# LPC55S14 register map
Vendor: nxp.com; File version: 1.0
CPU: CM33 r2p0, little endian, MPU, FPU, VTOR, 3 interrupt priority bits
Registers are 32-bit, read-write, reset 0x0 unless marked. A register's access mark holds for its fields unless they carry their own. Offsets are from the block's base; [hi:lo] are bit positions; {n}, {i} and the like mark numbered series; 'fields as' and 'values as' point back to an identical list.

## PMC
Base 0x40020000
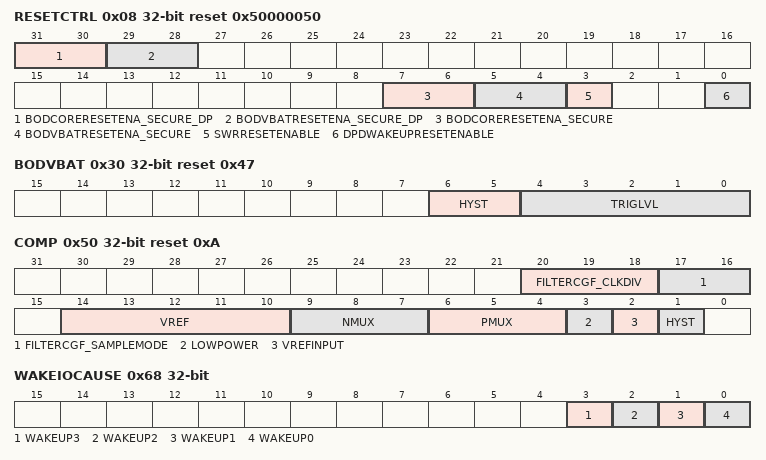
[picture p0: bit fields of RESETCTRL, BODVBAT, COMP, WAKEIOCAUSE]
0x08 RESETCTRL reset 0x50000050 — Reset Control [Reset by: PoR, Pin Reset, Brown Out Detectors Reset, Deep Power Down Reset, Software Reset]
  [31:30] BODCORERESETENA_SECURE_DP — BOD Core reset enable.
    1=ENABLE (Any other value than b10, BOD Core reset is enable.); 2=DISABLE (BOD Core reset is disable.)
  [29:28] BODVBATRESETENA_SECURE_DP — BOD VBAT reset enable.
    1=ENABLE (Any other value than b10, BOD VBAT reset is enable.); 2=DISABLE (BOD VBAT reset is disable.)
  [7:6] BODCORERESETENA_SECURE — BOD Core reset enable.
    values as BODCORERESETENA_SECURE_DP
  [5:4] BODVBATRESETENA_SECURE — BOD VBAT reset enable.
    values as BODVBATRESETENA_SECURE_DP
  [3] SWRRESETENABLE — Software reset enable.
    0=DISABLE (Software reset is disable.); 1=ENABLE (Software reset is enable.)
  [0] DPDWAKEUPRESETENABLE — Wake-up from DEEP POWER DOWN reset event (either from wake up I/O or RTC or OS Event Timer).
    0=DISABLE (Reset event from DEEP POWER DOWN mode is disable.); 1=ENABLE (Reset event from DEEP POWER DOWN mode is enable.)
0x30 BODVBAT reset 0x47 — VBAT Brown Out Dectector (BoD) control register [Reset by: PoR, Pin Reset, Software Reset]
  [6:5] HYST — BoD Hysteresis control.
    0=HYST_25MV (25 mV.); 1=HYST_50MV (50 mV.); 2=HYST_75MV (75 mV.); 3=HYST_100MV (100 mV.)
  [4:0] TRIGLVL — BoD trigger level.
    0=V_1P00 (1.00 V.); 1=V_1P10 (1.10 V.); 2=V_1P20 (1.20 V.); 3=V_1P30 (1.30 V.); 4=V_1P40 (1.40 V.); 5=V_1P50 (1.50 V.); 6=V_1P60 (1.60 V.); 7=V_1P65 (1.65 V.); 8=V_1P70 (1.70 V.); 9=V_1P75 (1.75 V.); 10=V_1P80 (1.80 V.); 11=V_1P90 (1.90 V.); 12=V_2P00 (2.00 V.); 13=V_2P10 (2.10 V.); 14=V_2P20 (2.20 V.); 15=V_2P30 (2.30 V.); 16=V_2P40 (2.40 V.); 17=V_2P50 (2.50 V.); 18=V_2P60 (2.60 V.); 19=V_2P70 (2.70 V.); 20=V_2P80 (2.806 V.); 21=V_2P90 (2.90 V.); 22=V_3P00 (3.00 V.); 23=V_3P10 (3.10 V.); 24=V_3P20 (3.20 V.); {v}=V_3P30_{v-23} (3.30 V.) (v=25..31)
0x50 COMP reset 0xA — Analog Comparator control register [Reset by: PoR, Pin Reset, Brown Out Detectors Reset, Deep Power Down Reset, Software Reset]
  [20:18] FILTERCGF_CLKDIV — Filter Clock divider.
    0=FILTER_1CLK_PERIOD (Filter clock period duration equals 1 Analog Comparator clock period.); 1=FILTER_2CLK_PERIOD (Filter clock period duration equals 2 Analog Comparator clock period.); 2=FILTER_4CLK_PERIOD (Filter clock period duration equals 4 Analog Comparator clock period.); 3=FILTER_8CLK_PERIOD (Filter clock period duration equals 8 Analog Comparator clock period.); 4=FILTER_16CLK_PERIOD (Filter clock period duration equals 16 Analog Comparator clock period.); 5=FILTER_32CLK_PERIOD (Filter clock period duration equals 32 Analog Comparator clock period.); 6=FILTER_64CLK_PERIOD (Filter clock period duration equals 64 Analog Comparator clock period.); 7=FILTER_128CLK_PERIOD (Filter clock period duration equals 128 Analog Comparator clock period.)
  [17:16] FILTERCGF_SAMPLEMODE — Control the filtering of the Analog Comparator output.
    0=BYPASS (Bypass mode.); 1=FILTER1CLK (Filter 1 clock period.); 2=FILTER2CLK (Filter 2 clock period.); 3=FILTER3CLK (Filter 3 clock period.)
  [14:10] VREF — Control reference voltage step, per steps of (VREFINPUT/31).
  [9:7] NMUX — Control word for N multiplexer:.
    0=VREF (VREF (See field VREFINPUT).); 1=CMP0_A (Pin P0_0.); 2=CMP0_B (Pin P0_9.); 3=CMP0_C (Pin P0_18.); 4=CMP0_D (Pin P1_14.); 5=CMP0_E (Pin P2_23.)
  [6:4] PMUX — Control word for P multiplexer:.
    0=VREF (VREF (See fiedl VREFINPUT).); 1=CMP0_A (Pin P0_0.); 2=CMP0_B (Pin P0_9.); 3=CMP0_C (Pin P0_18.); 4=CMP0_D (Pin P1_14.); 5=CMP0_E (Pin P2_23.)
  [3] LOWPOWER — Low power mode.
    0=HIGHSPEED (High speed mode.); 1=LOWSPEED (Low power mode (Low speed).)
  [2] VREFINPUT — Dedicated control bit to select between internal VREF and VDDA (for the resistive ladder).
    0=INTERNALREF (Select internal VREF.); 1=VDDA (Select VDDA.)
  [1] HYST — Hysteris when hyst = '1'.
    0=DISABLE (Hysteresis is disable.); 1=ENABLE (Hysteresis is enable.)
0x68 WAKEIOCAUSE — Allows to identify the Wake-up I/O source from Deep Power Down mode
  [3] WAKEUP3 — Allows to identify Wake up I/O 3 as the wake-up source from Deep Power Down mode.
    0=NOEVENT (Last wake up from Deep Power down mode was NOT triggred by wake up I/O 3.); 1=EVENT (Last wake up from Deep Power down mode was triggred by wake up I/O 3.)
  [2] WAKEUP2 — Allows to identify Wake up I/O 2 as the wake-up source from Deep Power Down mode.
    0=NOEVENT (Last wake up from Deep Power down mode was NOT triggred by wake up I/O 2.); 1=EVENT (Last wake up from Deep Power down mode was triggred by wake up I/O 2.)
  [1] WAKEUP1 — Allows to identify Wake up I/O 1 as the wake-up source from Deep Power Down mode.
    0=NOEVENT (Last wake up from Deep Power down mode was NOT triggred by wake up I/O 1.); 1=EVENT (Last wake up from Deep Power down mode was triggred by wake up I/O 1.)
  [0] WAKEUP0 ro — Allows to identify Wake up I/O 0 as the wake-up source from Deep Power Down mode.
    0=NOEVENT (Last wake up from Deep Power down mode was NOT triggred by wake up I/O 0.); 1=EVENT (Last wake up from Deep Power down mode was triggred by wake up I/O 0.)
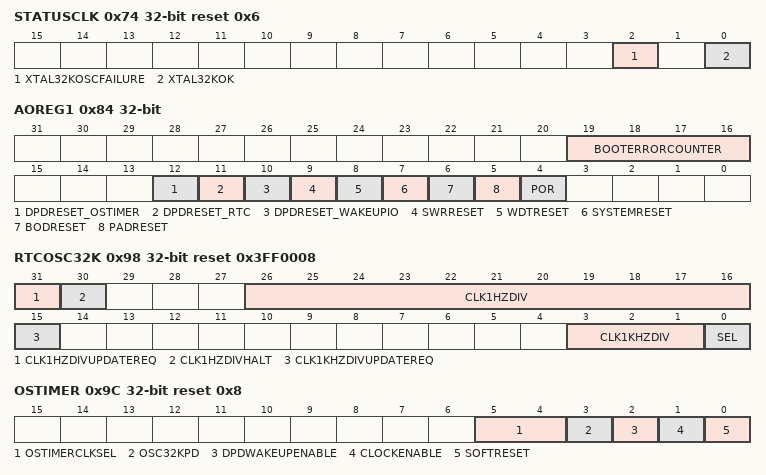
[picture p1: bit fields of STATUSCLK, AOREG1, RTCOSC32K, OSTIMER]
0x74 STATUSCLK reset 0x6 — FRO and XTAL status register [Reset by: PoR, Brown Out Detectors Reset]
  [2] XTAL32KOSCFAILURE — XTAL32 KHZ oscillator oscillation failure detection indicator.
    0=NOFAIL (No oscillation failure has been detetced since the last time this bit has been cleared..); 1=FAILURE (At least one oscillation failure has been detetced since the last time this bit has been cleared..)
  [0] XTAL32KOK ro — XTAL oscillator 32 K OK signal.
0x84 AOREG1 — General purpose always on domain data storage [Reset by: PoR, Brown Out Detectors Reset]
  [19:16] BOOTERRORCOUNTER — ROM Boot Fatal Error Counter.
  [12] DPDRESET_OSTIMER — The last chip reset was caused by an OS Event Timer reset event during a Deep Power-Down mode.
  [11] DPDRESET_RTC — The last chip reset was caused by an RTC (either RTC Alarm or RTC wake up) reset event during a Deep Power-Down mode.
  [10] DPDRESET_WAKEUPIO — The last chip reset was caused by a Wake-up I/O reset event during a Deep Power-Down mode.
  [9] SWRRESET — The last chip reset was caused by a Software event.
  [8] WDTRESET — The last chip reset was caused by the Watchdog Timer.
  [7] SYSTEMRESET — The last chip reset was caused by a System Reset requested by the ARM CPU.
  [6] BODRESET — The last chip reset was caused by a Brown Out Detector (BoD), either VBAT BoD or Core Logic BoD.
  [5] PADRESET — The last chip reset was caused by a Pin Reset.
  [4] POR — The last chip reset was caused by a Power On Reset.
0x98 RTCOSC32K reset 0x3FF0008 — RTC 1 KHZ and 1 Hz clocks source control register [Reset by: PoR, Brown Out Detectors Reset]
  [31] CLK1HZDIVUPDATEREQ — RTC 1Hz Divider status flag.
  [30] CLK1HZDIVHALT — Halts the divider counter.
  [26:16] CLK1HZDIV — Actual division ratio is : 31744 + CLK1HZDIV.
  [15] CLK1KHZDIVUPDATEREQ — RTC 1KHz clock Divider status flag.
  [3:1] CLK1KHZDIV — Actual division ratio is : 28 + CLK1KHZDIV.
  [0] SEL — Select the 32K oscillator to be used in Deep Power Down Mode for the RTC (either XTAL32KHz or FRO32KHz) .
    0=FRO32K (FRO 32 KHz.); 1=XTAL32K (XTAL 32KHz.)
0x9C OSTIMER reset 0x8 — OS Timer control register [Reset by: PoR, Brown Out Detectors Reset]
  [5:4] OSTIMERCLKSEL — OS event timer clock select.
    0=ENUM_0x0 (Oscillator 32 kHz clock.); 1=ENUM_0x1 (FRO 1MHz clock.); 2=ENUM_0x2 (Main clock for OS timer.); 3=ENUM_0x3 (No clock.)
  [3] OSC32KPD — Oscilator 32KHz (either FRO32KHz or XTAL32KHz according to RTCOSC32K.
  [2] DPDWAKEUPENABLE — Wake up enable in Deep Power Down mode (To be used in Enable Deep Power Down mode).
  [1] CLOCKENABLE — Enable OSTIMER 32 KHz clock.
  [0] SOFTRESET — Active high reset.
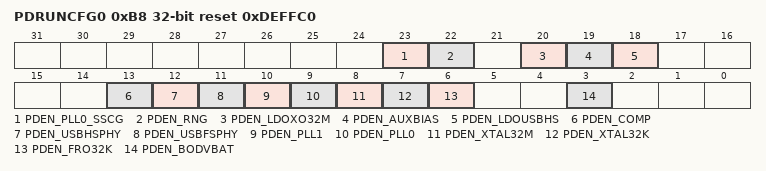
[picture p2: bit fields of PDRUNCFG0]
0xB8 PDRUNCFG0 reset 0xDEFFC0 — Controls the power to various analog blocks [Reset by: PoR, Pin Reset, Brown Out Detectors Reset, Deep Power Down Reset, Software Reset]
  [23] PDEN_PLL0_SSCG — Controls power to System PLL (PLL0) Spread Spectrum module.
    0=POWEREDON (PLL0 Sread spectrum module is powered.); 1=POWEREDOFF (PLL0 Sread spectrum module is powered down.)
  [22] PDEN_RNG — Controls power to all True Random Number Genetaor (TRNG) clock sources.
    0=POWEREDON (TRNG clocks are powered.); 1=POWEREDOFF (TRNG clocks are powered down.)
  [20] PDEN_LDOXO32M — Controls power to high speed crystal LDO.
    0=POWEREDON (High speed crystal LDO is powered.); 1=POWEREDOFF (High speed crystal LDO is powered down.)
  [19] PDEN_AUXBIAS — Controls power to auxiliary biasing (AUXBIAS)
    0=POWEREDON (auxiliary biasing is powered.); 1=POWEREDOFF (auxiliary biasing is powered down.)
  [18] PDEN_LDOUSBHS — Controls power to USB high speed LDO.
    0=POWEREDON (USB high speed LDO is powered.); 1=POWEREDOFF (USB high speed LDO is powered down.)
  [13] PDEN_COMP — Controls power to Analog Comparator.
    0=POWEREDON (Analog Comparator is powered.); 1=POWEREDOFF (Analog Comparator is powered down.)
  [12] PDEN_USBHSPHY — Controls power to USB High Speed Phy.
    0=POWEREDON (USB HS phy is powered.); 1=POWEREDOFF (USB HS phy is powered down.)
  [11] PDEN_USBFSPHY — Controls power to USB Full Speed phy.
    0=POWEREDON (USB Full Speed phy is powered.); 1=POWEREDOFF (USB Full Speed phy is powered down.)
  [10] PDEN_PLL1 — Controls power to USB PLL (also refered as PLL1).
    0=POWEREDON (PLL1 is powered.); 1=POWEREDOFF (PLL1 is powered down.)
  [9] PDEN_PLL0 — Controls power to System PLL (also refered as PLL0).
    0=POWEREDON (PLL0 is powered.); 1=POWEREDOFF (PLL0 is powered down.)
  [8] PDEN_XTAL32M — Controls power to high speed crystal.
    0=POWEREDON (High speed crystal is powered.); 1=POWEREDOFF (High speed crystal is powered down.)
  [7] PDEN_XTAL32K — Controls power to crystal 32 KHz.
    0=POWEREDON (Crystal 32KHz is powered.); 1=POWEREDOFF (Crystal 32KHz is powered down.)
  [6] PDEN_FRO32K — Controls power to the Free Running Oscillator (FRO) 32 KHz.
    0=POWEREDON (FRO32KHz is powered.); 1=POWEREDOFF (FRO32KHz is powered down.)
  [3] PDEN_BODVBAT — Controls power to VBAT Brown Out Detector (BOD).
    0=POWEREDON (BOD VBAT is powered.); 1=POWEREDOFF (BOD VBAT is powered down.)
0xC0 PDRUNCFGSET0 wo — Controls the power to various analog blocks [Reset by: PoR, Pin Reset, Brown Out Detectors Reset, Deep Power Down Reset, Software Reset]
  [31:0] PDRUNCFGSET0 — Writing ones to this register sets the corresponding bit or bits in the PDRUNCFG0 register, if they are implemented.
0xC8 PDRUNCFGCLR0 wo — Controls the power to various analog blocks [Reset by: PoR, Pin Reset, Brown Out Detectors Reset, Deep Power Down Reset, Software Reset]
  [31:0] PDRUNCFGCLR0 — Writing ones to this register clears the corresponding bit or bits in the PDRUNCFG0 register, if they are implemented.
